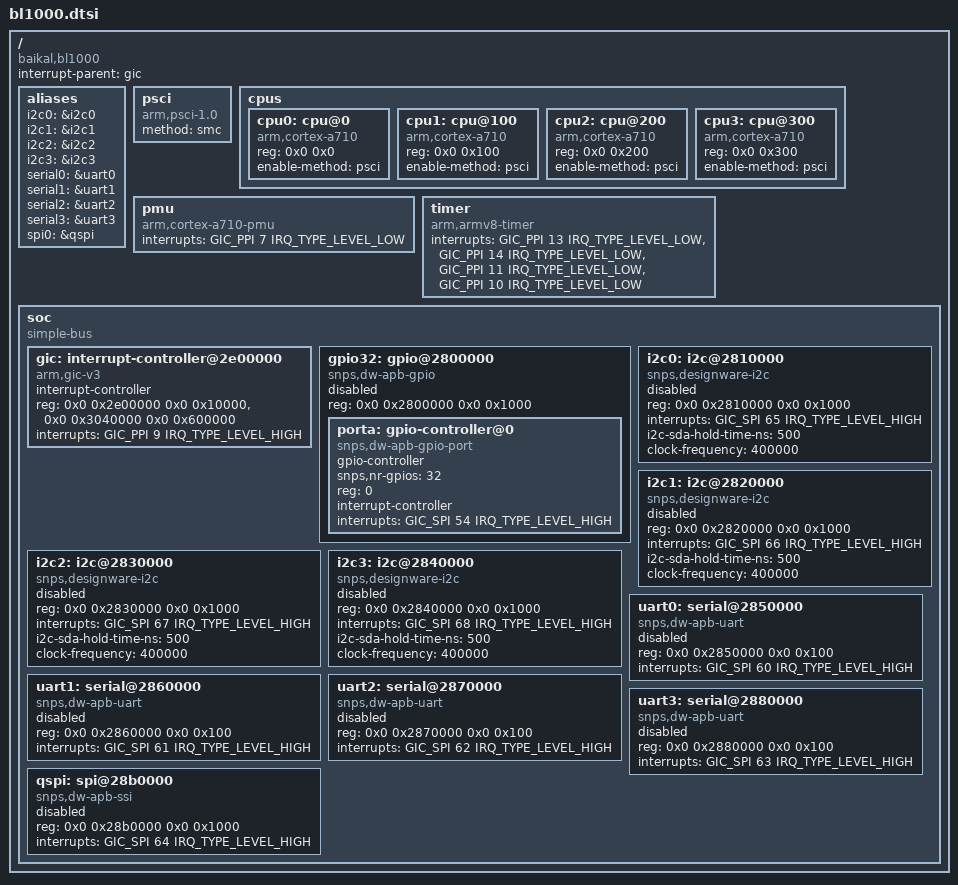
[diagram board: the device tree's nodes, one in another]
// SPDX-License-Identifier: GPL-2.0
/*
 * Device tree include file for BE-L1000 SoC
 * Copyright (C) 2022 Baikal Electronics, JSC
 */

#include <dt-bindings/interrupt-controller/arm-gic.h>

/ {
	compatible = "baikal,bl1000";
	#address-cells = <2>;
	#size-cells = <2>;
	interrupt-parent = <&gic>;

	aliases {
		i2c0	= &i2c0;
		i2c1	= &i2c1;
		i2c2	= &i2c2;
		i2c3	= &i2c3;
		serial0	= &uart0;
		serial1	= &uart1;
		serial2	= &uart2;
		serial3	= &uart3;
		spi0	= &qspi;
	};

	psci {
		compatible = "arm,psci-1.0", "arm,psci-0.2";
		method = "smc";
	};

	cpus {
		#address-cells = <2>;
		#size-cells = <0>;

		cpu0: cpu@0 {
			device_type = "cpu";
			compatible = "arm,cortex-a710";
			reg = <0x0 0x0>;
			enable-method = "psci";
		};

		cpu1: cpu@100 {
			device_type = "cpu";
			compatible = "arm,cortex-a710";
			reg = <0x0 0x100>;
			enable-method = "psci";
		};

		cpu2: cpu@200 {
			device_type = "cpu";
			compatible = "arm,cortex-a710";
			reg = <0x0 0x200>;
			enable-method = "psci";
		};

		cpu3: cpu@300 {
			device_type = "cpu";
			compatible = "arm,cortex-a710";
			reg = <0x0 0x300>;
			enable-method = "psci";
		};
	};

	pmu {
		compatible = "arm,cortex-a710-pmu";
		interrupts = <GIC_PPI 7 IRQ_TYPE_LEVEL_LOW>;
	};

	timer {
		compatible = "arm,armv8-timer";
		interrupts = <GIC_PPI 13 IRQ_TYPE_LEVEL_LOW>,
			     <GIC_PPI 14 IRQ_TYPE_LEVEL_LOW>,
			     <GIC_PPI 11 IRQ_TYPE_LEVEL_LOW>,
			     <GIC_PPI 10 IRQ_TYPE_LEVEL_LOW>;
	};

	soc {
		compatible = "simple-bus";
		#address-cells = <2>;
		#size-cells = <2>;
		ranges;

		gic: interrupt-controller@2e00000 {
			compatible = "arm,gic-v3";
			#interrupt-cells = <3>;
			#address-cells = <2>;
			#size-cells = <2>;
			ranges;
			interrupt-controller;
			reg = <0x0 0x2e00000 0x0 0x10000>,  /* GICD */
			      <0x0 0x3040000 0x0 0x600000>; /* GICR */
			      /* TODO: optional ranges - GICC, GICH, GICV */
			interrupts = <GIC_PPI 9 IRQ_TYPE_LEVEL_HIGH>;
		};

		gpio32: gpio@2800000 {
			compatible = "snps,dw-apb-gpio";
			reg = <0x0 0x2800000 0x0 0x1000>;
			#address-cells = <1>;
			#size-cells = <0>;
			status = "disabled";

			porta: gpio-controller@0 {
				compatible = "snps,dw-apb-gpio-port";
				gpio-controller;
				#gpio-cells = <2>;
				snps,nr-gpios = <32>;
				reg = <0>;
				interrupt-controller;
				#interrupt-cells = <2>;
				interrupts = <GIC_SPI 54 IRQ_TYPE_LEVEL_HIGH>;
			};
		};

		i2c0: i2c@2810000 {
			compatible = "snps,designware-i2c";
			#address-cells = <1>;
			#size-cells = <0>;
			reg = <0x0 0x2810000 0x0 0x1000>;
			interrupts = <GIC_SPI 65 IRQ_TYPE_LEVEL_HIGH>;
			i2c-sda-hold-time-ns = <500>;
			clock-frequency = <400000>;
			status = "disabled";
		};

		i2c1: i2c@2820000 {
			compatible = "snps,designware-i2c";
			#address-cells = <1>;
			#size-cells = <0>;
			reg = <0x0 0x2820000 0x0 0x1000>;
			interrupts = <GIC_SPI 66 IRQ_TYPE_LEVEL_HIGH>;
			i2c-sda-hold-time-ns = <500>;
			clock-frequency = <400000>;
			status = "disabled";
		};

		i2c2: i2c@2830000 {
			compatible = "snps,designware-i2c";
			#address-cells = <1>;
			#size-cells = <0>;
			reg = <0x0 0x2830000 0x0 0x1000>;
			interrupts = <GIC_SPI 67 IRQ_TYPE_LEVEL_HIGH>;
			i2c-sda-hold-time-ns = <500>;
			clock-frequency = <400000>;
			status = "disabled";
		};

		i2c3: i2c@2840000 {
			compatible = "snps,designware-i2c";
			#address-cells = <1>;
			#size-cells = <0>;
			reg = <0x0 0x2840000 0x0 0x1000>;
			interrupts = <GIC_SPI 68 IRQ_TYPE_LEVEL_HIGH>;
			i2c-sda-hold-time-ns = <500>;
			clock-frequency = <400000>;
			status = "disabled";
		};

		uart0: serial@2850000 {
			compatible = "snps,dw-apb-uart";
			reg = <0x0 0x2850000 0x0 0x100>;
			interrupts = <GIC_SPI 60 IRQ_TYPE_LEVEL_HIGH>;
			status = "disabled";
		};

		uart1: serial@2860000 {
			compatible = "snps,dw-apb-uart";
			reg = <0x0 0x2860000 0x0 0x100>;
			interrupts = <GIC_SPI 61 IRQ_TYPE_LEVEL_HIGH>;
			status = "disabled";
		};

		uart2: serial@2870000 {
			compatible = "snps,dw-apb-uart";
			reg = <0x0 0x2870000 0x0 0x100>;
			interrupts = <GIC_SPI 62 IRQ_TYPE_LEVEL_HIGH>;
			status = "disabled";
		};

		uart3: serial@2880000 {
			compatible = "snps,dw-apb-uart";
			reg = <0x0 0x2880000 0x0 0x100>;
			interrupts = <GIC_SPI 63 IRQ_TYPE_LEVEL_HIGH>;
			status = "disabled";
		};

		qspi: spi@28b0000 {
			compatible = "snps,dw-apb-ssi";
			reg = <0x0 0x28b0000 0x0 0x1000>;
			#address-cells = <1>;
			#size-cells = <0>;
			interrupts = <GIC_SPI 64 IRQ_TYPE_LEVEL_HIGH>;
			status = "disabled";
		};
	};
};
